# R40 register map
Vendor: Allwinner; Series: R40; File version: 0.1
CPU: CA7 0, little endian, MPU, FPU, double-precision FPU, 0 interrupt priority bits
Registers are 32-bit, read-write, reset 0x0 unless marked. A register's access mark holds for its fields unless they carry their own. Offsets are from the block's base; [hi:lo] are bit positions; {n}, {i} and the like mark numbered series.

## UART0
Base 0x01C28000
Same registers: UART1 0x01C28400, UART2 0x01C28800, UART3 0x01C28C00, UART4 0x01C29000, UART5 0x01C29400, UART6 0x01C29800, UART7 0x01C29C00
0x00 UART_DLL — UART Divisor Latch Low Register
  [7:0] DLL — Divisor Latch Low Lower 8 bits of a 16-bit, read/write, Divisor Latch register that contains the baud rate divisor for the UART. This register may only be accessed when the bit is set and the UART is not busy ( = 0). The output baud rate is equal to the serial clock (sclk) frequency divided by sixteen times the value of the baud rate divisor, as follows: baud rate = (serial clock freq) / (16 * divisor). Note that with the Divisor Latch Registers ( and ) set to zero, the baud clock is disabled and no serial communications occur. Also, once the is set, at least 8 clock cycles of the slowest UART clock should be allowed to pass before transmitting or receiving data.
0x00 UART_RBR — UART Receive Buffer Register
  [7:0] RBR ro — Receiver Buffer Register Data byte received on the serial input port (sin) in UART mode, or the serial infrared input (sir_in) in infrared mode. The data in this register is valid only if the bit in the register is set. If in FIFO mode and FIFOs are enabled ( = 1), this register accesses the head of the receive FIFO. If the receive FIFO is full and this register is not read before the next data character arrives, then the data already in the FIFO is preserved, but any incoming data are lost and an overrun error occurs.
0x00 UART_THR — UART Transmit Holding Register
  [7:0] THR wo — Transmit Holding Register Data to be transmitted on the serial output port (sout) in UART mode or the serial infrared output (sir_out_n) in infrared mode. Data should only be written to when the bit is set. If in FIFO mode and FIFOs are enabled ( = 1) and is set, 16 number of characters of data may be written to the THR before the FIFO is full. Any attempt to write data when the FIFO is full results in the write data being lost.
0x04 UART_DLH — UART Divisor Latch High Register
  [7:0] DLH — Divisor Latch High Upper 8 bits of a 16-bit, read/write, Divisor Latch register that contains the baud rate divisor for the UART. This register may only be accessed when the bit is set and the UART is not busy ( = 0). The output baud rate is equal to the serial clock (sclk) frequency divided by sixteen times the value of the baud rate divisor, as follows: baud rate = (serial clock freq) / (16 * divisor). Note that with the Divisor Latch Registers ( and ) set to zero, the baud clock is disabled and no serial communications occur. Also, once the is set, at least 8 clock cycles of the slowest UART clock should be allowed to pass before transmitting or receiving data.
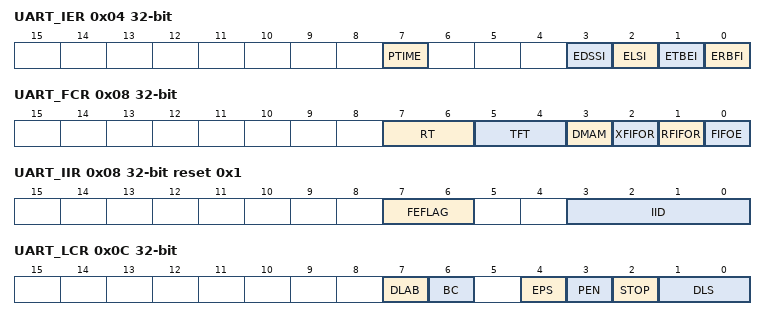
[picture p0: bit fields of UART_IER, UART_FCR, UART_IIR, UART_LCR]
0x04 UART_IER — UART Interrupt Enable Register
  [all] fields
    0=Disable; 1=Enable
  [7] PTIME — Programmable THRE Interrupt Mode Enable This is used to enable/disable the generation of THRE Interrupt. 0: Disable 1: Enable
  [3] EDSSI — Enable Modem Status Interrupt This is used to enable/disable the generation of Modem Status Interrupt. This is the fourth highest priority interrupt. 0: Disable 1: Enable
  [2] ELSI — Enable Receiver Line Status Interrupt This is used to enable/disable the generation of Receiver Line Status Interrupt. This is the highest priority interrupt. 0: Disable 1: Enable
  [1] ETBEI — Enable Transmit Holding Register Empty Interrupt This is used to enable/disable the generation of Transmitter Holding Register Empty Interrupt. This is the third highest priority interrupt. 0: Disable 1: Enable
  [0] ERBFI — Enable Received Data Available Interrupt This is used to enable/disable the generation of Received Data Available Interrupt and the Character Timeout Interrupt (if in FIFO mode and FIFOs enabled). These are the second highest priority interrupts. 0: Disable 1: Enable
0x08 UART_FCR — UART FIFO Control Register
  [7:6] RT wo — RCVR Trigger This is used to select the trigger level in the receiver FIFO at which the Received Data Available Interrupt is generated. In auto flow control mode it is used to determine when the rts_n signal is de-asserted. It also determines when the dma_rx_req_n signal is asserted in certain modes of operation. 00: 1 character in the FIFO 01: FIFO 25% full 10: FIFO 50% full 11: FIFO-2 less than full
    0=1 character in the FIFO; 1=FIFO_25_percent__full (FIFO 25% full); 2=FIFO_50_percent__full (FIFO 50% full); 3=FIFO_minus_2_less (FIFO-2 less than full)
  [5:4] TFT wo — TX Empty Trigger Writes have no effect when is disabled. This is used to select the empty threshold level at which the THRE Interrupts are generated when the mode is active. It also determines when the dma_tx_req_n signal is asserted when in certain modes of operation. 00: FIFO empty 01: 2 characters in the FIFO 10: FIFO 25% full 11: FIFO 50% full
    0=FIFO_empty; 1=2 characters in the FIFO; 2=FIFO_25_percent__full (FIFO 25% full); 3=FIFO_50_percent__full (FIFO 50% full)
  [3] DMAM wo — DMA Mode 0: Mode 0 1: Mode 1
    0=Mode_0; 1=Mode_1
  [2] XFIFOR wo — XMIT FIFO Reset This resets the control portion of the transmit FIFO and treats the FIFO as empty. This also de-asserts the DMA TX request. It is `self-clearing`. It is not necessary to clear this bit.
  [1] RFIFOR wo — RCVR FIFO Reset This resets the control portion of the receive FIFO and treats the FIFO as empty. This also de-asserts the DMA RX request. It is `self-clearing`. It is not necessary to clear this bit.
  [0] FIFOE wo — Enable FIFOs This enables/disables the transmit (XMIT) and receive (RCVR) FIFOs. Whenever the value of this bit is changed both the XMIT and RCVR controller portion of FIFOs is reset.
0x08 UART_IIR reset 0x1 — UART Interrupt Identity Register
  [7:6] FEFLAG ro — FIFOs Enable Flag This is used to indicate whether the FIFOs are enabled or disabled. 00: Disable 11: Enable
    0=Disable; 3=Enable
  [3:0] IID ro — Interrupt ID This indicates the highest priority pending interrupt which can be one of the following types: 0000: modem status 0001: no interrupt pending 0010: THR empty 0100: received data available 0110: receiver line status 0111: busy detect 1100: character timeout Bit 3 indicates an interrupt can only occur when the FIFOs are enabled and used to distinguish a Character Timeout condition interrupt.
    0=modem_status; 1=no interrupt pending; 2=THR_empty; 4=received data available; 6=receiver line status; 7=busy_detect; 12=character timeout Bit 3 indicates an interrupt can only occur when the FIFOs are enabled and used to distinguish a Character Timeout condition interrupt
0x0C UART_LCR — UART Line Control Register
  [7] DLAB — Divisor Latch Access Bit It is writeable only when UART is not busy ( = 0) and always readable. This bit is used to enable reading and writing of the Divisor Latch register ( and ) to set the baud rate of the UART. This bit must be cleared after initial baud rate setup in order to access other registers. 0: Select RX Buffer Register ( )/TX Holding Register ( ) and Interrupt Enable Register( ) 1: Select Divisor Latch Low Register( ) and Divisor Latch High Register( )
    0=Select RX Buffer Register ( )/TX Holding Register ( ) and Interrupt Enable Register( ); 1=Select Divisor Latch Low Register( ) and Divisor Latch High Register( )
  [6] BC — Break Control Bit This is used to cause a break condition to be transmitted to the receiving device. If set to one the serial output is forced to the spacing (logic 0) state. When not in , as determined by , the sout line is forced low until the Break bit is cleared. If SIR_MODE = Enabled and active ( is set to 1) the sir_out_n line is continuously pulsed. When in , the break condition is internally looped back to the receiver and the sir_out_n line is forced low.
  [4] EPS — Even Parity Select It is writeable only when UART is not busy ( = 0) and always writable readable. This is used to select between even and odd parity, when parity is enabled (PEN set to one). 0: Odd Parity 1: Even Parity
    0=Odd (Odd Parity); 1=Even Parity
  [3] PEN — Parity Enable It is writeable only when UART is not busy ( = 0) and always readable. This bit is used to enable and disable parity generation and detection in transmitted and received serial character respectively. 0: parity disabled 1: parity enabled
    0=parity_disabled; 1=parity_enabled
  [2] STOP — Number of stop bits It is writeable only when UART is not busy ( = 0) and always readable. This is used to select the number of stop bits per character that the peripheral transmits and receives. If set to zero, one stop bit is transmitted in the serial data. If the bit is set to `1` and the bit is set to 5, one and a half stop bit is transmitted. Otherwise, two stop bit is transmitted. Note that regardless of the number of stop bit selected, the receiver checks only the first stop bit. 0: 1 stop bit 1: 1.5 stop bit when is zero, else 2 stop bit
    0=1 stop bit; 1=_1_point_5 (1.5 stop bit when is zero, else 2 stop bit)
  [1:0] DLS — Data Length Select It is writeable only when UART is not busy ( = 0) and always readable. This is used to select the number of data bits per character that the peripheral transmits and receives. The number of bit that may be selected areas follows: 00: 5 bit 01: 6 bit 10: 7 bit 11: 8 bit
    {v}=_{v+5}_bit (v=0..3)
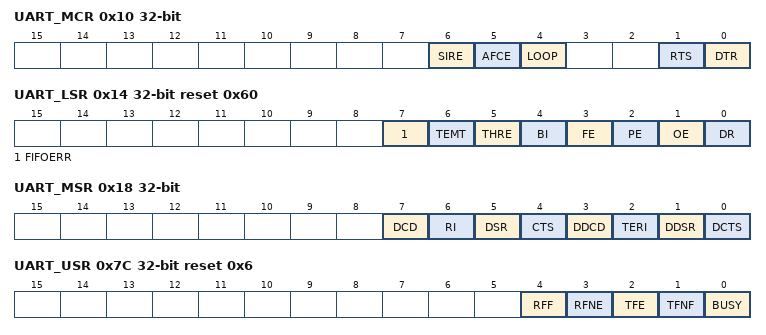
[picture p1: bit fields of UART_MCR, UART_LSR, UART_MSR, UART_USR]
0x10 UART_MCR — UART Modem Control Register
  [6] SIRE — SIR Mode Enable 0: IrDA SIR Mode disable 1: IrDA SIR Mode enable
    0=disable (IrDA SIR Mode disable); 1=enable (IrDA SIR Mode enable)
  [5] AFCE — Auto Flow Control Enable When FIFOs are enabled and the bit is set, Auto Flow Control features are enabled. 0: Auto Flow Control Mode disable 1: Auto Flow Control Mode enable
    0=disable (Auto Flow Control Mode disable); 1=enable (Auto Flow Control Mode enable)
  [4] LOOP — Loop Back Mode 0: Normal Mode 1: Loop Back Mode This is used to put the UART into a diagnostic mode for test purposes. If operating in UART mode ( is disabled), data on the sout line is held high, while serial data output is looped back to the sin line, internally. In this mode all the interrupts are fully functional. Also, in , the modem control inputs (dsr_n, cts_n, ri_n, dcd_n) are disconnected and the modem control outputs (dtr_n, rts_n, out1_n, out2_n) are looped back to the inputs, internally. If operating in infrared mode ( is enabled), data on the sir_out_n line is held low, while serial data output is inverted and looped back to the sir_in line.
    0=Normal Mode; 1=Loop Back Mode This is used to put the UART into a diagnostic mode for test purposes. If operating in UART mode ( is disabled), data on the sout line is held high, while serial data output is looped back to the sin line, internally. In this mode all the interrupts are fully functional. Also, in , the modem control inputs (dsr_n, cts_n, ri_n, dcd_n) are disconnected and the modem control outputs (dtr_n, rts_n, out1_n, out2_n) are looped back to the inputs, internally. If operating in infrared mode ( is enabled), data on the sir_out_n line is held low, while serial data output is inverted and looped back to the sir_in line.
  [1] RTS — Request to Send This is used to directly control the Request to Send (rts_n) output. The Request To Send (rts_n) output is used to inform the modem or data set that the UART is ready to exchange data. When Auto RTS Flow Control is not enabled ( = 0), the rts_n signal is set low by programming to high.In Auto Flow Control, AFCE_MODE is enabled and active ( = 1) and FIFOs enable ( = 1), the rts_n output is controlled in the same way, but is also gated with the receiver FIFO threshold trigger (rts_n is inactive high when above the threshold). The rts_n signal is de-asserted when is set low. 0: rts_n de-asserted (logic 1) 1: rts_n asserted (logic 0) Note that in Loopback mode ( = 1), the rts_n output is held inactive high while the value of this location is internally looped back to an input.
    0=n_deasserted (rts_n de-asserted (logic 1)); 1=n_asserted (rts_n asserted (logic 0) Note that in Loopback mode ( = 1), the rts_n output is held inactive high while the value of this location is internally looped back to an input.)
  [0] DTR — Data Terminal Ready This is used to directly control the (dtr_n) output. The value written to this location is inverted and driven out on dtr_n. 0:dtr_n de-asserted (logic 1) 1:dtr_n asserted (logic 0) The Data Terminal Ready output is used to inform the modem or data set that the UART is ready to establish communications. Note that in Loopback mode ( = 1), the dtr_n output is held inactive high while the value of this location is internally looped back to an input.
0x14 UART_LSR reset 0x60 — UART Line Status Register
  [7] FIFOERR ro — RX Data Error in FIFO When FIFOs are disabled, this bit is always 0. When FIFOs are enabled, this bit is set to 1 when there is at least one PE, FE, or BI in the RX FIFO. It is cleared by a read from the register provided there are no subsequent errors in the FIFO.
  [6] TEMT ro — Transmitter Empty If the FIFOs are disabled, this bit is set to "1" whenever the TX Holding Register and the TX Shift Register are empty. If the FIFOs are enabled, this bit is set whenever the TX FIFO and the TX Shift Register are empty. In both cases, this bit is cleared when a byte is written to the TX data channel.
  [5] THRE ro — TX Holding Register Empty If the FIFOs are disabled, this bit is set to `1` whenever the TX Holding Register is empty and ready to accept new data and it is cleared when the CPU writes to the TX Holding Register. If the FIFOs are enabled, this bit is set to `1` whenever the TX FIFO is empty and it is cleared when at least one byte is written to the TX FIFO.
  [4] BI ro — Break Interrupt This is used to indicate the detection of a break sequence on the serial input data. If in UART mode ( is disabled), it is set whenever the serial input, sin, is held in a logic `0` state for longer than the sum of start time + data bits + parity + stop . If in infrared mode ( is enabled), it is set whenever the serial input, sir_in, is continuously pulsed to logic `0` for longer than the sum of start time + data bits + parity + stop . A break condition on serial input causes one and only one character, consisting of all zeros, to be received by the UART. In the FIFO mode, the character associated with the break condition is carried through the FIFO and is revealed when the character is at the top of the FIFO. Reading the LSR clears the bit. In the non-FIFO mode, the indication occurs immediately and persists until the LSR is read.
  [3] FE ro — Framing Error This is used to indicate the occurrence of a framing error in the receiver. A framing error occurs when the receiver does not detect a valid STOP bit in the received data. In the FIFO mode, since the framing error is associated with a character received, it is revealed when the character with the framing error is at the top of the FIFO. When a framing error occurs, the UART tries to resynchronize. It does this by assuming that the error was due to the start bit of the next character and then continues receiving the other bit i.e. data, and/or parity and stop. It should be noted that the bit is set if a break interrupt has occurred, as indicated by the bit. 0: no framing error 1:framing error Reading the LSR clears the FE bit.
    0=no framing error 1:framing error Reading the LSR clears the FE bit
  [2] PE ro — Parity Error This is used to indicate the occurrence of a parity error in the receiver if the bit is set. In the FIFO mode, since the parity error is associated with a character received, it is revealed when the character with the parity error arrives at the top of the FIFO. It should be noted that the bit is set if a break interrupt has occurred, as indicated by the bit. 0: no parity error 1: parity error Reading the LSR clears the PE bit.
    0=no parity error; 1=parity error Reading the LSR clears the PE bit
  [1] OE ro — Overrun Error This occurs if a new data character was received before the previous data was read. In the non-FIFO mode, the bit is set when a new character arrives in the receiver before the previous character was read from the RBR. When this happens, the data in the RBR is overwritten. In the FIFO mode, an overrun error occurs when the FIFO is full and a new character arrives at the receiver. The data in the FIFO is retained and the data in the receive shift register is lost. 0: no overrun error 1: overrun error Reading the LSR clears the OE bit.
    0=no overrun error; 1=overrun error Reading the LSR clears the OE bit
  [0] DR ro — Data Ready This is used to indicate that the receiver contains at least one character in the RBR or the receiver FIFO. 0: no data ready 1: data ready This bit is cleared when the RBR is read in non-FIFO mode, or when the receiver FIFO is empty, in FIFO mode.
    0=no data ready; 1=data ready This bit is cleared when the RBR is read in non-FIFO mode, or when the receiver FIFO is empty, in FIFO mode
0x18 UART_MSR — UART Modem Status Register
  [7] DCD ro — Line State of Data Carrier Detect This is used to indicate the current state of the modem control line dcd_n. This bit is the complement of dcd_n. When the (dcd_n) is asserted, it is an indication that the carrier has been detected by the modem or data set. 0: dcd_n input is de-asserted (logic 1) 1: dcd_n input is asserted (logic 0)
    0=deasserted (dcd_n input is de-asserted (logic 1)); 1=asserted (dcd_n input is asserted (logic 0))
  [6] RI ro — Line State of Ring Indicator This is used to indicate the current state of the modem control line ri_n. This bit is the complement of ri_n. When the (ri_n) is asserted it is an indication that a telephone ringing signal has been received by the modem or data set. 0: ri_n input is de-asserted (logic 1) 1: ri_n input is asserted (logic 0)
    0=deasserted (ri_n input is de-asserted (logic 1)); 1=asserted (ri_n input is asserted (logic 0))
  [5] DSR ro — Line State of Data Set Ready This is used to indicate the current state of the modem control line dsr_n. This bit is the complement of dsr_n. When the (dsr_n) bit is asserted, it is an indication that the modem or data set is ready to establish communications with UART. 0: dsr_n input is de-asserted (logic 1) 1: dsr_n input is asserted (logic 0) In (UART_MCR[4] is set to 1), is the same as .
    0=deasserted (dsr_n input is de-asserted (logic 1)); 1=asserted (dsr_n input is asserted (logic 0) In (UART_MCR[4] is set to 1), is the same as .)
  [4] CTS ro — Line State of Clear To Send This is used to indicate the current state of the modem control line cts_n. This bit is the complement of cts_n. When the Clear to Send input (cts_n) is asserted it is an indication that the modem or data set is ready to exchange data with UART. 0: cts_n input is de-asserted (logic 1) 1: cts_n input is asserted (logic 0) In (UART_MCR[4] is set to 1), is the same as .
    0=deasserted (cts_n input is de-asserted (logic 1)); 1=asserted (cts_n input is asserted (logic 0) In (UART_MCR[4] is set to 1), is the same as .)
  [3] DDCD ro — Delta Data Carrier Detect This is used to indicate that the modem control line dcd_n has changed since the last time the MSR was read. 0: no change on dcd_n since last read of MSR 1: change on dcd_n since last read of MSR Reading the MSR clears the DDCD bit. Note: If the bit is not set and the dcd_n signal is asserted (low) and a reset occurs (software or otherwise), then the DDCD bit is set when the reset is removed if the dcd_n signal remains asserted.
    0=no change on dcd_n since last read of MSR; 1=change on dcd_n since last read of MSR Reading the MSR clears the DDCD bit. Note: If the bit is not set and the dcd_n signal is asserted (low) and a reset occurs (software or otherwise), then the DDCD bit is set when the reset is removed if the dcd_n signal remains asserted.
  [2] TERI ro — Trailing Edge Ring Indicator This is used to indicate that a change on the input ri_n (from an active-low to an inactive-high state) has occurred since the last time the MSR was read. 0: no change on ri_n since last read of MSR 1: change on ri_n since last read of MSR Reading the MSR clears the TERI bit.
    0=no change on ri_n since last read of MSR; 1=change on ri_n since last read of MSR Reading the MSR clears the TERI bit
  [1] DDSR ro — Delta Data Set Ready This is used to indicate that the modem control line dsr_n has changed since the last time the MSR was read. 0: no change on dsr_n since last read of MSR 1: change on dsr_n since last read of MSR Reading the MSR clears the DDSR bit. In (UART_MCR[4] = 1), DDSR reflects changes on . Note: If the DDSR bit is not set and the dsr_n signal is asserted (low) and a reset occurs (software or otherwise), then the DDSR bit is set when the reset is removed if the dsr_n signal remains asserted.
    0=no change on dsr_n since last read of MSR; 1=change on dsr_n since last read of MSR Reading the MSR clears the DDSR bit. In (UART_MCR[4] = 1), DDSR reflects changes on . Note: If the DDSR bit is not set and the dsr_n signal is asserted (low) and a reset occurs (software or otherwise), then the DDSR bit is set when the reset is removed if the dsr_n signal remains asserted.
  [0] DCTS ro — Delta Clear to Send This is used to indicate that the modem control line cts_n has changed since the last time the MSR was read. 0: no change on ctsdsr_n since last read of MSR 1: change on ctsdsr_n since last read of MSR Reading the MSR clears the DCTS bit. In (UART_MCR[4] = 1), reflects changes on . Note: If the bit is not set and the cts_n signal is asserted (low) and a reset occurs (software or otherwise), then the bit is set when the reset is removed if the cts_n signal remains asserted.
    0=no change on ctsdsr_n since last read of MSR; 1=change on ctsdsr_n since last read of MSR Reading the MSR clears the DCTS bit. In (UART_MCR[4] = 1), reflects changes on . Note: If the bit is not set and the cts_n signal is asserted (low) and a reset occurs (software or otherwise), then the bit is set when the reset is removed if the cts_n signal remains asserted.
0x1C UART_SCH — UART Scratch Register
  [7:0] SCRATCH_REG — Scratch Register This register is for programmers to use as a temporary storage space. It has no defined purpose in the UART.
0x7C UART_USR reset 0x6 — UART Status Register
  [4] RFF ro — Receive FIFO Full This is used to indicate that the receive FIFO is completely full. 0: Receive FIFO not full 1: Receive FIFO full This bit is cleared when the RX FIFO is no longer full.
    0=Receive FIFO not full; 1=Receive FIFO full This bit is cleared when the RX FIFO is no longer full
  [3] RFNE ro — Receive FIFO Not Empty This is used to indicate that the receive FIFO contains one or more entries. 0: Receive FIFO is empty 1: Receive FIFO is not empty This bit is cleared when the RX FIFO is empty.
    0=empty (Receive FIFO is empty); 1=not_empty (Receive FIFO is not empty This bit is cleared when the RX FIFO is empty.)
  [2] TFE ro — Transmit FIFO Empty This is used to indicate that the transmit FIFO is completely empty. 0: Transmit FIFO is not empty 1: Transmit FIFO is empty This bit is cleared when the TX FIFO is no longer empty.
    0=not_empty (Transmit FIFO is not empty); 1=empty (Transmit FIFO is empty This bit is cleared when the TX FIFO is no longer empty.)
  [1] TFNF ro — Transmit FIFO Not Full This is used to indicate that the transmit FIFO is not full. 0: Transmit FIFO is full 1: Transmit FIFO is not full This bit is cleared when the TX FIFO is full.
    0=full (Transmit FIFO is full); 1=not_full (Transmit FIFO is not full This bit is cleared when the TX FIFO is full.)
  [0] BUSY ro — UART Busy Bit 0: Idle or inactive 1: Busy
    0=Idle or inactive; 1=Busy
0x80 UART_TFL — UART Transmit FIFO Level
  [6:0] TFL ro — Transmit FIFO Level This is indicates the number of data entries in the transmit FIFO.
0x84 UART_RFL — UART Receive FIFO Level
  [6:0] RFL ro — Receive FIFO Level This is indicates the number of data entries in the receive FIFO.
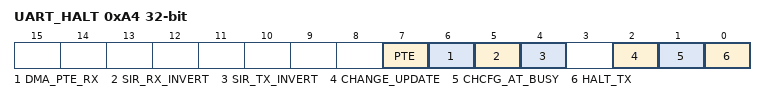
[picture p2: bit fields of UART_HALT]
0xA4 UART_HALT — UART Halt TX Register
  [7] PTE — TX_REQ Transmit In DMA1 mode ( is 1,FIFO is open),if PTE signal is high, DMA request is sent when TFL is not larger than TRIG. If PTE signal is low, DMA request is sent when FIFO is empty. DMA request could fall when FIFO is full. In DMA0 mode( is 0,FIFO is closed),if PTE signal is high and FIFO is open, DMA request is sent when TFL is not larger than TRIG. If these conditions are not satisfied, then DRQ will fall. If PTE signal is high and FIFO is closed, DMA request is sent when THRE is empty. If these conditions are not satisfied, then DRQ will fall. If PTE signal is low, DMA request is sent when FIFO is empty.
  [6] DMA_PTE_RX — RX_DRQ Receive In DMA1 mode, when RFL is not less than TRIG or the receiver timeout is happened, DRQ is sent , or else DRQ is low. In DMA0 mode, if DMA_PTE_RX is 1 and FIFO is open, REQ is sent when RFL is not less than TRIG, or else not sent.
  [5] SIR_RX_INVERT — SIR Receiver Pulse Polarity Invert 0: Not invert receiver signal 1: Invert receiver signal
    0=Not invert receiver signal; 1=Invert receiver signal
  [4] SIR_TX_INVERT — SIR Transmit Pulse Polarity Invert 0: Not invert transmit pulse 1: Invert transmit pulse
    0=Not invert transmit pulse; 1=Invert transmit pulse
  [2] CHANGE_UPDATE — After the user using to change the baud rate or register configuration, write 1 to update the configuration and waiting this bit self clear to 0 to finish update process. Write 0 to this bit has no effect. 1: Update trigger, Self clear to 0 when finish update.
    1=Update trigger, Self clear to 0 when finish update
  [1] CHCFG_AT_BUSY — This is an enable bit for the user to change register configuration (except for the bit) and baudrate register ( and ) when the UART is busy ( is 1). 1: Enable change when busy
    1=Enable change when busy
  [0] HALT_TX — Halt TX This register is used to halt transmissions for testing, so that the transmit FIFO can be filled by the master when FIFOs are implemented and enabled. 0: Halt TX disabled 1: Halt TX enabled Note: If FIFOs are not enabled, the setting of the halt TX register has no effect on operation.
    0=disabled (Halt TX disabled); 1=enabled (Halt TX enabled Note: If FIFOs are not enabled, the setting of the halt TX register has no effect on operation.)
